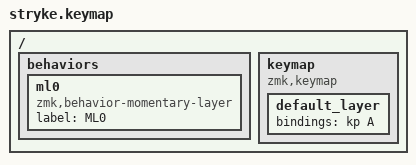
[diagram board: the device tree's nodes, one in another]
#include <dt-bindings/zmk/keys.h>

/ {
    behaviors {
        ml0: ml0 {
            compatible = "zmk,behavior-momentary-layer";
            label = "ML0";
            #binding-cells = <1>;
        };
    };

    keymap {
        compatible = "zmk,keymap";

        default_layer {
            bindings = <
                &kp A
            >;
        };
    };
};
